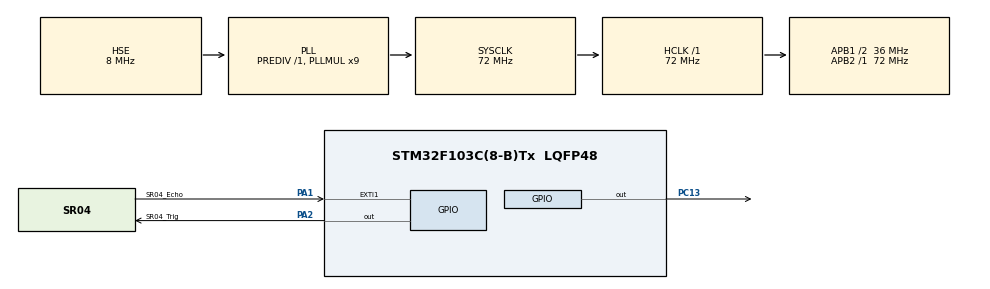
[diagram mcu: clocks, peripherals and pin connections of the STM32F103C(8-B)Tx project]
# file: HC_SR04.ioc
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Mcu.Family=STM32F1
Mcu.Name=STM32F103C(8-B)Tx
Mcu.Package=LQFP48
NVIC.EXTI1_IRQn=true\:1\:0\:true\:false\:true\:true\:true\:true
NVIC.PriorityGroup=NVIC_PRIORITYGROUP_4
PA1.GPIO_Label=SR04_Echo
PA1.GPIO_ModeDefaultEXTI=GPIO_MODE_IT_RISING_FALLING
PA1.GPIO_PuPd=GPIO_PULLUP
PA1.Signal=GPXTI1
PA13.Mode=Serial_Wire
PA13.Signal=SYS_JTMS-SWDIO
PA14.Mode=Serial_Wire
PA14.Signal=SYS_JTCK-SWCLK
PA2.GPIO_Label=SR04_Trig
PA2.Signal=GPIO_Output
PC13-TAMPER-RTC.Signal=GPIO_Output
PD0-OSC_IN.Mode=HSE-External-Oscillator
PD0-OSC_IN.Signal=RCC_OSC_IN
PD1-OSC_OUT.Mode=HSE-External-Oscillator
PD1-OSC_OUT.Signal=RCC_OSC_OUT
ProjectManager.HeapSize=0x200
ProjectManager.StackSize=0x400
ProjectManager.TargetToolchain=MDK-ARM V5.32
RCC.AHBFreq_Value=72000000
RCC.APB1CLKDivider=RCC_HCLK_DIV2
RCC.APB1Freq_Value=36000000
RCC.APB1TimFreq_Value=72000000
RCC.APB2Freq_Value=72000000
RCC.APB2TimFreq_Value=72000000
RCC.HCLKFreq_Value=72000000
RCC.PLLMUL=RCC_PLL_MUL9
RCC.PLLSourceVirtual=RCC_PLLSOURCE_HSE
RCC.SYSCLKFreq_VALUE=72000000
RCC.SYSCLKSource=RCC_SYSCLKSOURCE_PLLCLK
RCC.USBFreq_Value=72000000
TIM2.Prescaler=71
VP_TIM2_VS_ClockSourceINT.Mode=Internal
board=custom

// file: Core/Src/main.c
/* USER CODE BEGIN Header */
/**
  ******************************************************************************
  * @file           : main.c
  * @brief          : Main program body
  ******************************************************************************
  * @attention
  *
  * Copyright (c) 2022 STMicroelectronics.
  * All rights reserved.
  *
  * This software is licensed under terms that can be found in the LICENSE file
  * in the root directory of this software component.
  * If no LICENSE file comes with this software, it is provided AS-IS.
  *
  ******************************************************************************
  */
/* USER CODE END Header */
#include "main.h"

 TIM_HandleTypeDef htim2;

void SystemClock_Config(void);
static void MX_GPIO_Init(void);
static void MX_TIM2_Init(void);
/* USER CODE BEGIN PFP */
#include <stdbool.h>
float kc;
uint32_t time_start;

typedef enum
{
	HCR04_IDLE_STATE,
	HCR04_GEN_PULSE_STATE,
	HCR04_START_STATE,
	HCR04_DONE_STATE,
}HCSR04_State_t;

HCSR04_State_t hc_state;
bool sta_hc =0;
/* USER CODE END PFP */

/* USER CODE BEGIN 0 */
void HAL_GPIO_EXTI_Callback(uint16_t GPIO_Pin)
{
	if(hc_state ==HCR04_START_STATE)
	{
		if(GPIO_Pin == SR04_Echo_Pin)
		{
			if(HAL_GPIO_ReadPin(SR04_Echo_GPIO_Port,SR04_Echo_Pin) == 1)//canh len
			{
				//cnt =0;
				htim2.Instance->CNT = 0;
				HAL_TIM_Base_Start(&htim2);
			}
			else//canh xuong
			{
				kc = htim2.Instance->CNT*0.017;
				HAL_TIM_Base_Stop(&htim2);
				hc_state = HCR04_DONE_STATE;
			}
		}
	}
}
void hcsr04_start()
{
	if(hc_state == HCR04_IDLE_STATE)
	{
		HAL_GPIO_WritePin(SR04_Trig_GPIO_Port,
											SR04_Trig_Pin,
											GPIO_PIN_SET);
		hc_state = HCR04_GEN_PULSE_STATE;
		time_start = HAL_GetTick();
//				HAL_Delay(1);
//				HAL_GPIO_WritePin(SR04_Trig_GPIO_Port,
//													SR04_Trig_Pin,
//													GPIO_PIN_RESET);
//				time_start = HAL_GetTick();
//				hc_state = HCR04_START_STATE;
	}
}
void hcsr04_handle()
{
	switch(hc_state)
	{
		case HCR04_IDLE_STATE:
			break;
		case HCR04_GEN_PULSE_STATE:
			if(HAL_GetTick() - time_start >=1)
			{
				HAL_GPIO_WritePin(SR04_Trig_GPIO_Port,
												SR04_Trig_Pin,
												GPIO_PIN_RESET);
				time_start = HAL_GetTick();
				hc_state = HCR04_START_STATE;
			}
			break;
		case HCR04_START_STATE:
			if(HAL_GetTick() - time_start >= 1000)
			{
				//cam bien hong
				hc_state = HCR04_IDLE_STATE;
				sta_hc = 1;
			}

			break;
		case HCR04_DONE_STATE:
			//in ra man hinh
			//hien thi lcd,
			 sta_hc =0;
			 hc_state = HCR04_IDLE_STATE;
			break;
	}
}
/* USER CODE END 0 */

int main(void)
{

  /* MCU Configuration--------------------------------------------------------*/

  /* Reset of all peripherals, Initializes the Flash interface and the Systick. */
  HAL_Init();

  /* Configure the system clock */
  SystemClock_Config();

  /* Initialize all configured peripherals */
  MX_GPIO_Init();
  MX_TIM2_Init();
  /* USER CODE BEGIN 2 */
	hc_state = HCR04_IDLE_STATE;
  /* USER CODE END 2 */

  /* Infinite loop */
  while (1)
  {

    /* USER CODE BEGIN 3 */
		static uint32_t t_old;
		if(HAL_GetTick() - t_old >=300)
		{
			hcsr04_start();
			t_old =HAL_GetTick();
		}
		hcsr04_handle();

		static uint32_t t_blink;
		if(sta_hc &&(HAL_GetTick() -t_blink >=500))
		{
			HAL_GPIO_TogglePin(GPIOC,GPIO_PIN_13);
			t_blink = HAL_GetTick();
		}

  }
  /* USER CODE END 3 */
}

void SystemClock_Config(void)
{
  RCC_OscInitTypeDef RCC_OscInitStruct = {0};
  RCC_ClkInitTypeDef RCC_ClkInitStruct = {0};

  /** Initializes the RCC Oscillators according to the specified parameters
  * in the RCC_OscInitTypeDef structure.
  */
  RCC_OscInitStruct.OscillatorType = RCC_OSCILLATORTYPE_HSE;
  RCC_OscInitStruct.HSEState = RCC_HSE_ON;
  RCC_OscInitStruct.HSEPredivValue = RCC_HSE_PREDIV_DIV1;
  RCC_OscInitStruct.HSIState = RCC_HSI_ON;
  RCC_OscInitStruct.PLL.PLLState = RCC_PLL_ON;
  RCC_OscInitStruct.PLL.PLLSource = RCC_PLLSOURCE_HSE;
  RCC_OscInitStruct.PLL.PLLMUL = RCC_PLL_MUL9;
  if (HAL_RCC_OscConfig(&RCC_OscInitStruct) != HAL_OK)
  {
    Error_Handler();
  }

  /** Initializes the CPU, AHB and APB buses clocks
  */
  RCC_ClkInitStruct.ClockType = RCC_CLOCKTYPE_HCLK|RCC_CLOCKTYPE_SYSCLK
                              |RCC_CLOCKTYPE_PCLK1|RCC_CLOCKTYPE_PCLK2;
  RCC_ClkInitStruct.SYSCLKSource = RCC_SYSCLKSOURCE_PLLCLK;
  RCC_ClkInitStruct.AHBCLKDivider = RCC_SYSCLK_DIV1;
  RCC_ClkInitStruct.APB1CLKDivider = RCC_HCLK_DIV2;
  RCC_ClkInitStruct.APB2CLKDivider = RCC_HCLK_DIV1;

  if (HAL_RCC_ClockConfig(&RCC_ClkInitStruct, FLASH_LATENCY_2) != HAL_OK)
  {
    Error_Handler();
  }
}

static void MX_TIM2_Init(void)
{

  TIM_ClockConfigTypeDef sClockSourceConfig = {0};
  TIM_MasterConfigTypeDef sMasterConfig = {0};

  htim2.Instance = TIM2;
  htim2.Init.Prescaler = 71;
  htim2.Init.CounterMode = TIM_COUNTERMODE_UP;
  htim2.Init.Period = 65535;
  htim2.Init.ClockDivision = TIM_CLOCKDIVISION_DIV1;
  htim2.Init.AutoReloadPreload = TIM_AUTORELOAD_PRELOAD_DISABLE;
  if (HAL_TIM_Base_Init(&htim2) != HAL_OK)
  {
    Error_Handler();
  }
  sClockSourceConfig.ClockSource = TIM_CLOCKSOURCE_INTERNAL;
  if (HAL_TIM_ConfigClockSource(&htim2, &sClockSourceConfig) != HAL_OK)
  {
    Error_Handler();
  }
  sMasterConfig.MasterOutputTrigger = TIM_TRGO_RESET;
  sMasterConfig.MasterSlaveMode = TIM_MASTERSLAVEMODE_DISABLE;
  if (HAL_TIMEx_MasterConfigSynchronization(&htim2, &sMasterConfig) != HAL_OK)
  {
    Error_Handler();
  }

}

static void MX_GPIO_Init(void)
{
  GPIO_InitTypeDef GPIO_InitStruct = {0};

  /* GPIO Ports Clock Enable */
  __HAL_RCC_GPIOC_CLK_ENABLE();
  __HAL_RCC_GPIOD_CLK_ENABLE();
  __HAL_RCC_GPIOA_CLK_ENABLE();

  /*Configure GPIO pin Output Level */
  HAL_GPIO_WritePin(GPIOC, GPIO_PIN_13, GPIO_PIN_RESET);

  /*Configure GPIO pin Output Level */
  HAL_GPIO_WritePin(GPIOA, GPIO_PIN_2, GPIO_PIN_RESET);

  /*Configure GPIO pin : PC13 */
  GPIO_InitStruct.Pin = GPIO_PIN_13;
  GPIO_InitStruct.Mode = GPIO_MODE_OUTPUT_PP;
  GPIO_InitStruct.Pull = GPIO_NOPULL;
  GPIO_InitStruct.Speed = GPIO_SPEED_FREQ_LOW;
  HAL_GPIO_Init(GPIOC, &GPIO_InitStruct);

  /*Configure GPIO pin : PA1 */
  GPIO_InitStruct.Pin = GPIO_PIN_1;
  GPIO_InitStruct.Mode = GPIO_MODE_IT_RISING_FALLING;
  GPIO_InitStruct.Pull = GPIO_PULLUP;
  HAL_GPIO_Init(GPIOA, &GPIO_InitStruct);

  /*Configure GPIO pin : PA2 */
  GPIO_InitStruct.Pin = GPIO_PIN_2;
  GPIO_InitStruct.Mode = GPIO_MODE_OUTPUT_PP;
  GPIO_InitStruct.Pull = GPIO_NOPULL;
  GPIO_InitStruct.Speed = GPIO_SPEED_FREQ_LOW;
  HAL_GPIO_Init(GPIOA, &GPIO_InitStruct);

  /* EXTI interrupt init*/
  HAL_NVIC_SetPriority(EXTI1_IRQn, 1, 0);
  HAL_NVIC_EnableIRQ(EXTI1_IRQn);

}

void Error_Handler(void)
{
  __disable_irq();
  while (1)
  {
  }
}
